# R40 register map
Vendor: Allwinner; Series: R40; File version: 0.1
CPU: CA7 0, little endian, MPU, FPU, double-precision FPU, 0 interrupt priority bits
Registers are 32-bit, read-write, reset 0x0 unless marked. A register's access mark holds for its fields unless they carry their own. Offsets are from the block's base; [hi:lo] are bit positions.

## SMHC0
Base 0x01C0F000
Same registers: SMHC1 0x01C10000, SMHC2 0x01C11000, SMHC3 0x01C12000
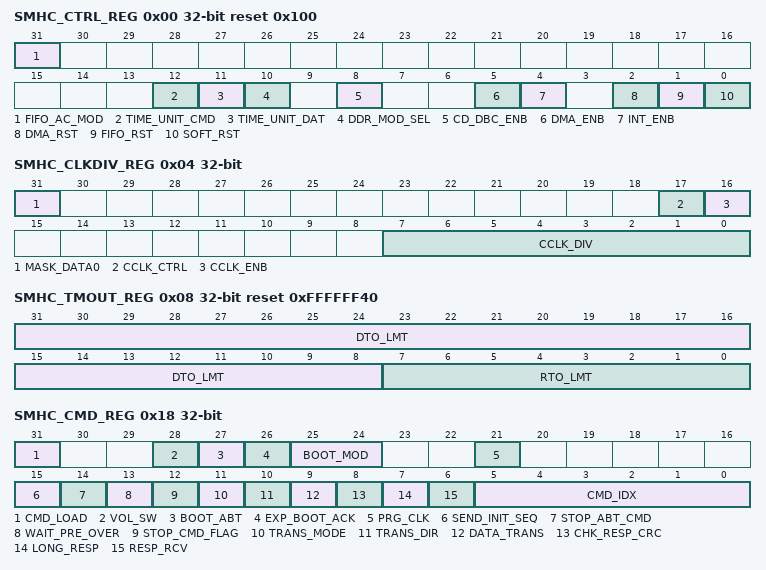
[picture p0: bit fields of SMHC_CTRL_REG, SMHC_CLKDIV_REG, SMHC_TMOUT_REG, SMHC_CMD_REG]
0x00 SMHC_CTRL_REG reset 0x100
  [31] FIFO_AC_MOD — FIFO Access Mode 0: DMA bus 1: AHB bus
    0=DMA (DMA bus); 1=AHB (AHB bus)
  [12] TIME_UNIT_CMD — Time unit for command line Time unit used to calculate command line time out value defined in RTO_LMT. 0: 1 card clock period 1: 256 card clock period
    0=1 card clock period; 1=256 card clock period
  [11] TIME_UNIT_DAT — Time unit for data line Time unit used to calculate data line time out value defined in . 0: 1 card clock period 1: 256 card clock period
    0=1 card clock period; 1=256 card clock period
  [10] DDR_MOD_SEL — DDR Mode Select 0: SDR mode 1: DDR mode
    0=SDR_mode; 1=DDR_mode
  [8] CD_DBC_ENB — Card Detect (Data[3] status) De-bounce Enable 0: Disable de-bounce 1: Enable de-bounce
    0=Disable de-bounce; 1=Enable de-bounce
  [5] DMA_ENB — DMA Global Enable 0: Disable DMA to transfer data, using AHB bus 1: Enable DMA to transfer data
    0=Disable DMA to transfer data, using AHB bus; 1=Enable DMA to transfer data
  [4] INT_ENB — Global Interrupt Enable 0: Disable interrupts 1: Enable interrupts
    0=Disable interrupts; 1=Enable interrupts
  [2] DMA_RST — DMA Reset
  [1] FIFO_RST — FIFO Reset 0: No change 1: Reset FIFO This bit is auto-cleared after completion of reset operation.
    0=No_change; 1=Reset FIFO This bit is auto-cleared after completion of reset operation
  [0] SOFT_RST — Software Reset 0: No change 1: Reset SD/MMC controller This bit is auto-cleared after completion of reset operation.
    0=No_change; 1=Reset SD/MMC controller This bit is auto-cleared after completion of reset operation
0x04 SMHC_CLKDIV_REG
  [31] MASK_DATA0 — 0: Do not mask data0 when update clock 1: Mask data0 when update clock
    0=Do not mask data0 when update clock; 1=Mask data0 when update clock
  [17] CCLK_CTRL — Card Clock Output Control 0: Card clock always on 1: Turn off card clock when FSM in IDLE state
    0=Card clock always on; 1=Turn off card clock when FSM in IDLE state
  [16] CCLK_ENB — Card Clock Enable 0: Card Clock off 1: Card Clock on
    0=Card_Clock_off; 1=Card_Clock_on
  [7:0] CCLK_DIV — Card clock divider n: Source clock is divided by 2*n.(n=0~255)
0x08 SMHC_TMOUT_REG reset 0xFFFFFF40
  [31:8] DTO_LMT — Data Timeout Limit
  [7:0] RTO_LMT — Response Timeout Limit
0x0C SMHC_BUSWID_REG
  [1:0] CARD_WID — Card width 00: 1-bit width 01: 4-bit width 1x: 8-bit width
    0=1-bit width; 1=4-bit width; 2=8-bit width
0x10 SMHC_BLKSIZ_REG reset 0x200
  [15:0] BLK_SZ — Block size
0x14 SMHC_BYTCNT_REG reset 0x200
  [31:0] BYTE_CNT — Byte counter Number of bytes to be transferred It should be integer multiple of Block Size for block transfers.
0x18 SMHC_CMD_REG
  [31] CMD_LOAD — Start Command. This bit is automatically cleared when current command is sent. If there is no any response error happened, a command complete interrupt bit (CMD_OVER) will be set in interrupt register. You should not write any other command before this bit is cleared, or a command busy interrupt bit (CMD_BUSY) will be set in interrupt register.
  [28] VOL_SW — Voltage Switch 0: Normal command 1: Voltage switch command, set for CMD11 only
    0=Normal command; 1=Voltage switch command, set for CMD11 only
  [27] BOOT_ABT — Boot Abort Setting this bit will terminate the boot operation.
  [26] EXP_BOOT_ACK — Expect Boot Acknowledge. When Software sets this bit along in mandatory boot operation, controller expects a boot acknowledge start pattern of 0-1-0 from the selected card.
  [25:24] BOOT_MOD — Boot Mode 00: Normal command 01: Mandatory Boot operation 10: Alternate Boot operation 11: Reserved
    0=Normal command; 1=Mandatory Boot operation; 2=Alternate Boot operation
  [21] PRG_CLK — Change Clock 0: Normal command 1: Change Card Clock; when this bit is set, controller will change clock domain and clock output. No command will be sent.
    0=Normal command; 1=Change Card Clock; when this bit is set, controller will change clock domain and clock output. No command will be sent.
  [15] SEND_INIT_SEQ — Send Initialization 0: Normal command sending 1: Send initialization sequence before sending this command.
    0=Normal command sending; 1=Send initialization sequence before sending this command
  [14] STOP_ABT_CMD — Stop Abort Command 0: Normal command sending 1: Send Stop or abort command to stop current data transfer in progress.(CMD12, CMD52 for writing `I/O Abort` in SDIO CCCR)
    0=Normal command sending; 1=Send Stop or abort command to stop current data transfer in progress.(CMD12, CMD52 for writing `I/O Abort` in SDIO CCCR)
  [13] WAIT_PRE_OVER — Wait Data Transfer Over 0: Send command at once, do not care of data transferring 1: Wait for data transfer completion before sending current command
    0=Send command at once, do not care of data transferring; 1=Wait for data transfer completion before sending current command
  [12] STOP_CMD_FLAG — Send Stop CMD Automatically (CMD12) 0: Do not send stop command at end of data transfer 1: Send stop command automatically at end of data transfer
    0=Do not send stop command at end of data transfer; 1=Send stop command automatically at end of data transfer
  [11] TRANS_MODE — Transfer Mode 0: Block data transfer command 1: Stream data transfer command
    0=Block data transfer command; 1=Stream data transfer command
  [10] TRANS_DIR — Transfer Direction 0: Read operation 1: Write operation
    0=Read operation; 1=Write operation
  [9] DATA_TRANS — Data Transfer 0: Without data transfer 1: With data transfer
    0=Without data transfer; 1=With data transfer
  [8] CHK_RESP_CRC — Check Response CRC 0: Do not check response CRC 1: Check response CRC
    0=Do not check response CRC; 1=Check response CRC
  [7] LONG_RESP — Response Type 0: Short Response (48 bit) 1: Long Response (136 bit)
    0=Short Response (48 bit); 1=Long Response (136 bit)
  [6] RESP_RCV — Response Receive 0: Command without Response 1: Command with Response
    0=Command_without_Response; 1=Command_with_Response
  [5:0] CMD_IDX — CMD Index Command index value
0x1C SMHC_CMDARG_REG
  [31:0] CMD_ARG — Command argument
0x20 SMHC_RESP0_REG
  [31:0] CMD_RESP0 ro — Response 0 Bit[31:0] of response
0x24 SMHC_RESP1_REG
  [31:0] CMD_RESP1 ro — Response 1 Bit[63:31] of response
0x28 SMHC_RESP2_REG
  [31:0] CMD_RESP2 ro — Response 2 Bit[95:64] of response
0x2C SMHC_RESP3_REG
  [31:0] CMD_RESP3 ro — Response 3 Bit[127:96] of response
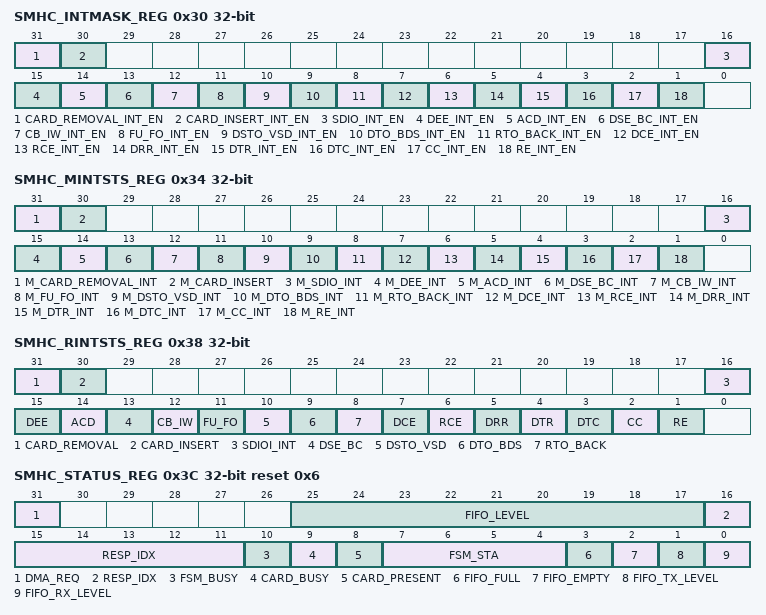
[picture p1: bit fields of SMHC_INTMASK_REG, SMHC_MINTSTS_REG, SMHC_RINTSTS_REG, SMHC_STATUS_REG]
0x30 SMHC_INTMASK_REG
  [31] CARD_REMOVAL_INT_EN — Card Removed Interrupt Enable
  [30] CARD_INSERT_INT_EN — Card Inserted Interrupt Enable
  [16] SDIO_INT_EN — SDIO Interrupt Enable
  [15] DEE_INT_EN — Data End-bit Error Interrupt Enable
  [14] ACD_INT_EN — Auto Command Done Interrupt Enable
  [13] DSE_BC_INT_EN — Data Start Error Interrupt Enable
  [12] CB_IW_INT_EN — Command Busy and Illegal Write Interrupt Enable
  [11] FU_FO_INT_EN — FIFO Underrun/Overflow Interrupt Enable
  [10] DSTO_VSD_INT_EN — Data Starvation Timeout/V1.8 Switch Done Interrupt Enable
  [9] DTO_BDS_INT_EN — Data Timeout/Boot Data Start Interrupt Enable
  [8] RTO_BACK_INT_EN — Response Timeout/Boot ACK Received Interrupt Enable
  [7] DCE_INT_EN — Data CRC Error Interrupt Enable
  [6] RCE_INT_EN — Response CRC Error Interrupt Enable
  [5] DRR_INT_EN — Data Receive Request Interrupt Enable
  [4] DTR_INT_EN — Data Transmit Request Interrupt Enable
  [3] DTC_INT_EN — Data Transfer Complete Interrupt Enable
  [2] CC_INT_EN — Command Complete Interrupt Enable
  [1] RE_INT_EN — Response Error Interrupt Enable
0x34 SMHC_MINTSTS_REG
  [31] M_CARD_REMOVAL_INT — Card Removed
  [30] M_CARD_INSERT — Card Inserted
  [16] M_SDIO_INT — SDIO Interrupt
  [15] M_DEE_INT — Data End-bit Error When set during receiving data, it means that host controller does not receive valid data end bit. When set during transmitting data, it means that host controller does not receive CRC status taken or received CRC status taken is negative.
  [14] M_ACD_INT — Auto Command Done When set, it means auto stop command(CMD12) completed.
  [13] M_DSE_BC_INT — Data Start Error When set during receiving data, it means that host controller found a error start bit. When set during transmitting data, it means that busy signal is cleared.
  [12] M_CB_IW_INT — Command Busy and Illegal Write
  [11] M_FU_FO_INT — FIFO Underrun/Overflow
  [10] M_DSTO_VSD_INT — Data Starvation Timeout/V1.8 Switch Done
  [9] M_DTO_BDS_INT — Data Timeout/Boot Data Start
  [8] M_RTO_BACK_INT — Response Timeout/Boot ACK Received
  [7] M_DCE_INT — Data CRC Error When set during receiving data, it means that the received data have data CRC error. When set during transmitting data, it means that the received CRC status taken is negative.
  [6] M_RCE_INT — Response CRC Error
  [5] M_DRR_INT — Data Receive Request When set, it means that there are enough data in FIFO during receiving data.
  [4] M_DTR_INT — Data Transmit Request When set, it means that there is enough space in FIFO during transmitting data.
  [3] M_DTC_INT — Data Transfer Complete
  [2] M_CC_INT — Command Complete
  [1] M_RE_INT — Response Error (no response or response CRC error) When set, Transmit Bit error or End Bit error or CMD Index error may occur.
0x38 SMHC_RINTSTS_REG
  [31] CARD_REMOVAL write-1-clears — Card Removed This is write-1-to-clear bit.
  [30] CARD_INSERT write-1-clears — Card Inserted This is write-1-to-clear bit.
  [16] SDIOI_INT write-1-clears — SDIO Interrupt This is write-1-to-clear bit.
  [15] DEE write-1-clears — Data End-bit Error When set during receiving data, it means that host controller does not receive valid data end bit. When set during transmitting data, it means that host controller does not receive CRC status taken. This is write-1-to-clear bit.
  [14] ACD write-1-clears — Auto Command Done When set, it means auto stop command(CMD12) completed. This is write-1-to-clear bit.
  [13] DSE_BC write-1-clears — Data Start Error When set during receiving data, it means that host controller found a error start bit. When set during transmitting data, it means that busy signal is cleared. This is write-1-to-clear bit.
  [12] CB_IW write-1-clears — Command Busy and Illegal Write This is write-1-to-clear bit.
  [11] FU_FO write-1-clears — FIFO Underrun/Overflow This is write-1-to-clear bit.
  [10] DSTO_VSD write-1-clears — Data Starvation Timeout/V1.8 Switch Done This is write-1-to-clear bit.
  [9] DTO_BDS write-1-clears — Data Timeout/Boot Data Start This is write-1-to-clear bit.
  [8] RTO_BACK write-1-clears — Response Timeout/Boot ACK Received This is write-1-to-clear bit.
  [7] DCE write-1-clears — Data CRC Error When set during receiving data, it means that the received data have data CRC error. When set during transmitting data, it means that the received CRC status taken is negative. This is write-1-to-clear bit.
  [6] RCE write-1-clears — Response CRC Error This is write-1-to-clear bit.
  [5] DRR write-1-clears — Data Receive Request When set, it means that there are enough data in FIFO during receiving data. This is write-1-to-clear bit.
  [4] DTR write-1-clears — Data Transmit Request When set, it means that there is enough space in FIFO during transmitting data. This is write-1-to-clear bit.
  [3] DTC write-1-clears — Data Transfer Complete This is write-1-to-clear bit.
  [2] CC write-1-clears — Command Complete This is write-1-to-clear bit.
  [1] RE write-1-clears — Response Error (no response or response CRC error) When set, Transmit Bit error or End Bit error or CMD Index error may occur. This is write-1-to-clear bit.
0x3C SMHC_STATUS_REG reset 0x6
  [31] DMA_REQ ro — DMA Request DMA request signal state
  [25:17] FIFO_LEVEL ro — FIFO Level Number of filled locations in FIFO
  [16:11] RESP_IDX ro — Response Index Index of previous response, including any auto-stop sent by controller
  [10] FSM_BUSY ro — Data FSM Busy Data transmit or receive state-machine is busy
  [9] CARD_BUSY ro — Card data busy Inverted version of DATA[0] 0: Card data not busy 1: Card data busy
    0=Card_data_not_busy; 1=Card_data_busy
  [8] CARD_PRESENT ro — Data[3] status level of DATA[3]; checks whether card is present 0: Card not present 1: Card present
    0=Card_not_present; 1=Card_present
  [7:4] FSM_STA ro — Command FSM states 0000: Idle 0001: Send init sequence 0010: TX CMD start bit 0011: TX CMD TX bit 0100: TX CMD index + argument 0101: TX CMD CRC7 0110: TX CMD end bit 0111: RX response start bit 1000: RX response IRQ response 1001: RX response TX bit 1010: RX response CMD index 1011: RX response data 1100: RX response CRC7 1101: RX response end bit 1110: CMD path wait NCC 1111: Wait; CMD-to-response turnaround
  [3] FIFO_FULL ro — FIFO full 0: FIFO not full 1: FIFO full
    0=FIFO (FIFO not full); 1=FIFO_full
  [2] FIFO_EMPTY ro — FIFO Empty 0: FIFO not empty 1: FIFO empty
    0=FIFO (FIFO not empty); 1=FIFO_empty
  [1] FIFO_TX_LEVEL ro — FIFO TX Water Level flag 0: FIFO didn`t reach transmit trigger level 1: FIFO reached transmit trigger level
    0=FIFO didn`t reach transmit trigger level; 1=FIFO reached transmit trigger level
  [0] FIFO_RX_LEVEL ro — FIFO TX Water Level flag 0: FIFO didn`t reach receive trigger level 1: FIFO reached receive trigger level
    0=FIFO didn`t reach receive trigger level; 1=FIFO reached receive trigger level
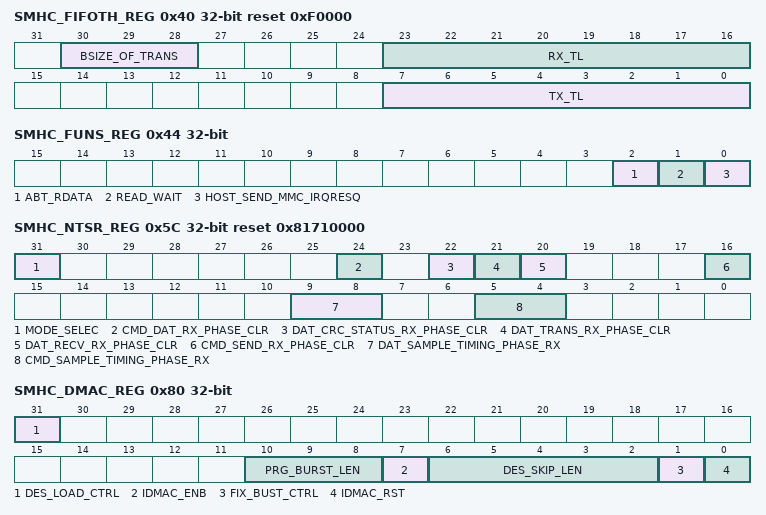
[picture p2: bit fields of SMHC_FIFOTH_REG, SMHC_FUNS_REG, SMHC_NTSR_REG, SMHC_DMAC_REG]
0x40 SMHC_FIFOTH_REG reset 0xF0000
  [30:28] BSIZE_OF_TRANS — Burst size of multiple transaction 000: 1 transfers 001: 4 010: 8 011: 16 (only SMHC2 support) Others: Reserved Should be programmed same as DMA controller multiple transaction size. The units for transfers are the DWORD. A single transfer would be signaled based on this value. Value should be sub-multiple of (RX_TL + 1) and (FIFO_DEPTH - TX_TL) Recommended: MSize = 16, TX_TL = 240, RX_TL = 15(SMHC2) MSize = 8, TX_TL = 248, RX_TL = 7(for SMHC0/1)
    0=1 transfers; 1=_4; 2=_8; 3=16 (only SMHC2 support) Others: Reserved Should be programmed same as DMA controller multiple transaction size. The units for transfers are the DWORD. A single transfer would be signaled based on this value. Value should be sub-multiple of (RX_TL + 1) and (FIFO_DEPTH - TX_TL) Recommended: MSize = 16, TX_TL = 240, RX_TL = 15(SMHC2) MSize = 8, TX_TL = 248, RX_TL = 7(for SMHC0/1)
  [23:16] RX_TL — RX Trigger Level 0x0~0xFE: RX Trigger Level is 0~254 0xFF reserved FIFO threshold when FIFO request host to receive data from FIFO. When FIFO data level is greater than this value, DMA request is raised if DMA enabled, or RX interrupt bit is set if interrupt enabled. At the end of packet, if the last transfer is less than this level, the value is ignored and relative request will be raised as usual. Recommended: 15 (means greater than 15)(SMHC2)
  [7:0] TX_TL — TX Trigger Level 0x1~0xFF: TX Trigger Level is 1~255 0x0: no trigger FIFO threshold when FIFO requests host to transmit data to FIFO. When FIFO data level is less than or equal to this value, DMA TX request is raised if DMA enabled, or TX request interrupt bit is set if interrupt enabled. At the end of packet, if the last transfer is less than this level, the value is ignored and relative request will be raised as usual. Recommended: 240(means less than or equal to 240)(SMHC2)
    0=no trigger FIFO threshold when FIFO requests host to transmit data to FIFO. When FIFO data level is less than or equal to this value, DMA TX request is raised if DMA enabled, or TX request interrupt bit is set if interrupt enabled. At the end of packet, if the last transfer is less than this level, the value is ignored and relative request will be raised as usual. Recommended: 240(means less than or equal to 240)(SMHC2)
0x44 SMHC_FUNS_REG
  [2] ABT_RDATA — Abort Read Data 0: Ignored 1: After suspend command is issued during read-transfer, software polls card to find when suspend happened. Once suspend occurs, software sets the bit to reset data state-machine, which is waiting for next block of data. Used in SDIO card suspends sequence. This bit is auto-cleared once controller reset to idle state.
    0=Ignored; 1=After suspend command is issued during read-transfer, software polls card to find when suspend happened. Once suspend occurs, software sets the bit to reset data state-machine, which is waiting for next block of data. Used in SDIO card suspends sequence. This bit is auto-cleared once controller reset to idle state.
  [1] READ_WAIT — Read Wait 0: Clear SDIO read wait 1: Assert SDIO read wait
    0=Clear SDIO read wait; 1=Assert SDIO read wait
  [0] HOST_SEND_MMC_IRQRESQ — Host Send MMC IRQ Response 0: Ignored 1: Send auto IRQ response When host is waiting MMC card interrupt response, setting this bit will make controller cancel wait state and return to idle state, at which time, controller will receive IRQ response sent by itself. This bit is auto-cleared after response is sent.
    0=Ignored; 1=Send auto IRQ response When host is waiting MMC card interrupt response, setting this bit will make controller cancel wait state and return to idle state, at which time, controller will receive IRQ response sent by itself. This bit is auto-cleared after response is sent.
0x48 SMHC_TBC_REG0
  [31:0] TBC0 ro — Transferred Count 0 Number of bytes transferred between card and internal FIFO. The register should be accessed in full to avoid read-coherency problems and read only after data transfer completes.
0x4C SMHC_TBC_REG1
  [31:0] TBC1 ro — Transferred Count 1 Number of bytes transferred between card and internal FIFO. The register should be accessed in full to avoid read-coherency problems and read only after data transfer completes.
0x54 SMHC_CSDC reset 0x3 — CRC Status Detect Control Register
  [3:0] CRC_DET_PARA — 0110: HS400 speed mode 0011: Other speed mode
    6=HS400 (HS400 speed mode); 3=Other speed mode
0x58 SMHC_A12A_REG reset 0xFFFF
  [15:0] SD_A12A — SD_A12A set the argument of command 12 automatically send by controller
0x5C SMHC_NTSR_REG reset 0x81710000
  [31] MODE_SELEC — 0: Old mode of Sample/Output Timing 1: New mode of Sample/Output Timing
    0=Old mode of Sample/Output Timing; 1=New mode of Sample/Output Timing
  [24] CMD_DAT_RX_PHASE_CLR — During update clock , command and data rx phase clear 0: Disable 1: Enable
    0=Disable; 1=Enable
  [22] DAT_CRC_STATUS_RX_PHASE_CLR — Before receive CRC status, data rx phase clear 0: Disable 1: Enable
    0=Disable; 1=Enable
  [21] DAT_TRANS_RX_PHASE_CLR — Before transfer data , data rx phase clear 0: Disable 1: Enable
    0=Disable; 1=Enable
  [20] DAT_RECV_RX_PHASE_CLR — Before receive data , data rx phase clear 0: Disable 1: Enable
    0=Disable; 1=Enable
  [16] CMD_SEND_RX_PHASE_CLR — Before send command, command rx phase clear 0: Disable 1: Enable
    0=Disable; 1=Enable
  [9:8] DAT_SAMPLE_TIMING_PHASE_RX — DAT_SAMPLE_TIMING_PHASE(RX) 00: Sample timing phase offset 90 01: Sample timing phase offset 180 10: Sample timing phase offset 270 11: Ignore
  [5:4] CMD_SAMPLE_TIMING_PHASE_RX — CMD_SAMPLE_TIMING_PHASE(RX) 00: Sample timing phase offset 90 01: Sample timing phase offset 180 10: Sample timing phase offset 270 11: Ignore
0x78 SMHC_HWRST_REG reset 0x1
  [0] HW_RST — 0: Reset 1: Active mode These bits cause the cards to enter pre-idle state, which requires them to be re-initialized.
    0=Reset; 1=Active mode These bits cause the cards to enter pre-idle state, which requires them to be re-initialized
0x80 SMHC_DMAC_REG
  [31] DES_LOAD_CTRL wo — When DMAC fetches a descriptor, if the valid bit of a descriptor is not set, DMAC FSM will go to the suspend state. Setting this bit will make DMAC re-fetch descriptor again and do the transfer normally.
  [10:8] PRG_BURST_LEN ro — Programmable Burst Length. These bits indicate the maximum number of beats to be performed in one IDMAC transaction. The IDMAC will always attempt to burst as specified in PBL each time it starts a Burst transfer on the host bus. The permissible values are 1, 4, 8, 16, 32, 64, 128 and 256. This value is the mirror of MSIZE of FIFOTH register. In order to change this value, write the required value to FIFOTH register. This is an encode value as follows. 000: 1 transfers 001: 4 transfers 010: 8 transfers 011: 16 transfers Transfer unit is 32bits. PBL is a read-only value.
    0=1 transfers; 1=4 transfers; 2=8 transfers; 3=16 transfers Transfer unit is 32bits. PBL is a read-only value.
  [7] IDMAC_ENB — IDMAC Enable. When set, the IDMAC is enabled. DE is read/write.
  [6:2] DES_SKIP_LEN — Descriptor Skip Length. Specifies the number of Word to skip between two unchained descriptors. This is applicable only for dual buffer structure. Default value is set to 4 DWORD.
  [1] FIX_BUST_CTRL — Fixed Burst. Controls whether the AHB Master interface performs fixed burst transfers or not. When set, the AHB will use only SINGLE, INCR4, INCR8 during start of normal burst transfers. When reset, the AHB will use SINGLE and INCR burst transfer operations.
  [0] IDMAC_RST — DMA Reset. When set, the DMA Controller resets all its internal registers. SWR is read/write. It is automatically cleared after 1 clock cycle.
0x84 SMHC_DLBA_REG
  [31:0] DES_BASE_ADDR — Start of Descriptor List. Contains the base address of the First Descriptor. The LSB bit[1:0] are ignored and taken as all-zero by the IDMAC internally. Hence these LSB bits are read-only.
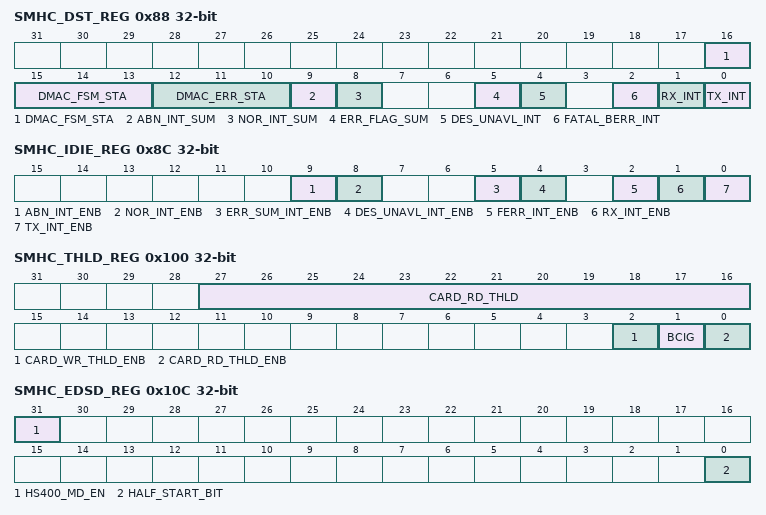
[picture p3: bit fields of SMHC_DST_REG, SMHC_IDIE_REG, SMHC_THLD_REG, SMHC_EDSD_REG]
0x88 SMHC_DST_REG
  [16:13] DMAC_FSM_STA ro — DMAC FSM present state. 0000: DMA_IDLE 0001: DMA_SUSPEND 0010: DESC_RD 0011: DESC_CHK 0100: DMA_RD_REQ_WAIT 0101: DMA_WR_REQ_WAIT 0110: DMA_RD 0111: DMA_WR 1000: DESC_CLOSE This bit is read-only.
    0=DMA_IDLE; 1=DMA_SUSPEND; 2=DESC_RD; 3=DESC_CHK; 4=DMA_RD_REQ_WAIT; 5=DMA_WR_REQ_WAIT; 6=DMA_RD; 7=DMA_WR; 8=DESC_CLOSE (DESC_CLOSE This bit is read-only.)
  [12:10] DMAC_ERR_STA ro — Error Bits. Indicates the type of error that caused a Bus Error. Valid only with Fatal Bus Error bit ( ) set. This field does not generate an interrupt. 001: Host Abort received during transmission 010: Host Abort received during reception Others: Reserved EB is read-only.
    1=Host_Abort_received_during_transmission; 2=Host Abort received during reception
  [9] ABN_INT_SUM write-1-clears — Abnormal Interrupt Summary. Logical OR of the following: IDSTS[2]: Fatal Bus Interrupt IDSTS[4]: DU bit Interrupt IDSTS[5]: Card Error Summary Interrupt Only unmasked bits affect this bit. This is a sticky bit and must be cleared each time a corresponding bit that causes AIS to be set is cleared. Writing a 1 clears this bit.
  [8] NOR_INT_SUM write-1-clears — Normal Interrupt Summary. Logical OR of the following: IDSTS[0]: Transmit Interrupt IDSTS[1]: Receive Interrupt Only unmasked bits affect this bit. This is a sticky bit and must be cleared each time a corresponding bit that causes NIS to be set is cleared. Writing a 1 clears this bit.
  [5] ERR_FLAG_SUM write-1-clears — Card Error Summary. Indicates the status of the transaction to/from the card; also present in RINTSTS. Indicates the logical OR of the following bits: EBE: End Bit Error RTO: Response Timeout/Boot ACK Timeout RCRC: Response CRC SBE: Start Bit Error DRTO: Data Read Timeout/BDS timeout DCRC: Data CRC for Receive RE: Response Error Writing a 1 clears this bit.
  [4] DES_UNAVL_INT write-1-clears — Descriptor Unavailable Interrupt. This bit is set when the descriptor is unavailable due to OWN bit = 0 (DES0[31] =0). Writing a 1 clears this bit.
  [2] FATAL_BERR_INT write-1-clears — Fatal Bus Error Interrupt. Indicates that a Bus Error occurred ( ). When this bit is set, the DMA disables all its bus accesses. Writing a `1` clears this bit.
  [1] RX_INT write-1-clears — Receive Interrupt. Indicates the completion of data reception for a descriptor. Writing a `1` clears this bit.
  [0] TX_INT write-1-clears — Transmit Interrupt. Indicates that data transmission is finished for a descriptor. Writing a `1` clears this bit.
0x8C SMHC_IDIE_REG
  [9] ABN_INT_ENB — Abnormal Interrupt Summary Enable. When set, an abnormal interrupt is enabled. This bit enables the following bits: IDINTEN[2]: Fatal Bus Error Interrupt IDINTEN[4]: DU Interrupt IDINTEN[5]: Card Error Summary Interrupt
  [8] NOR_INT_ENB — Normal Interrupt Summary Enable. When set, a normal interrupt is enabled. When reset, a normal interrupt is disabled. This bit enables the following bits: IDINTEN[0]: Transmit Interrupt IDINTEN[1]: Receive Interrupt
  [5] ERR_SUM_INT_ENB — Card Error summary Interrupt Enable. When set, it enables the Card Interrupt summary.
  [4] DES_UNAVL_INT_ENB — Descriptor Unavailable Interrupt. When set along with Abnormal Interrupt Summary Enable, the DU interrupt is enabled.
  [2] FERR_INT_ENB — Fatal Bus Error Enable. When set with Abnormal Interrupt Summary Enable, the Fatal Bus Error Interrupt is enabled. When reset, Fatal Bus Error Enable Interrupt is disabled.
  [1] RX_INT_ENB — Receive Interrupt Enable. When set with Normal Interrupt Summary Enable, Receive Interrupt is enabled. When reset, Receive Interrupt is disabled.
  [0] TX_INT_ENB — Transmit Interrupt Enable. When set with Normal Interrupt Summary Enable, Transmit Interrupt is enabled. When reset, Transmit Interrupt is disabled.
0x90 SMHC_CHDA_REG
  [31:0] CUR_DES_ADDR ro — Host Descriptor Address Pointer. Cleared on reset. Pointer updated by IDMAC during operation. This register points to the start address of the current descriptor read by the IDMAC.
0x94 SMHC_CBDA_REG
  [31:0] CUR_BUFF_ADDR ro — Host Buffer Address Pointer. Cleared on Reset. Pointer updated by IDMAC during operation. This register points to the current Data Buffer Address being accessed by the IDMAC.
0x100 SMHC_THLD_REG
  [27:16] CARD_RD_THLD — Card Read Threshold Size
  [2] CARD_WR_THLD_ENB — (only for SMHC2 ) Card Write Threshold Enable(HS400) 0: Card Write Threshold Disable 1: Card Write Threshold Enabled Host controller initiates write transfer only if card threshold amount of data is available in transmit FIFO
    0=Card_Write_Threshold_Disable; 1=Card Write Threshold Enabled Host controller initiates write transfer only if card threshold amount of data is available in transmit FIFO
  [1] BCIG — (only for SMHC2) Busy Clear Interrupt Generation 0: Busy Clear Interrupt Disabled 1: Busy Clear Interrupt Enabled The application can disable this feature if it does not want to wait for a Busy Clear Interrupt.
    0=Busy_Clear_Interrupt_Disabled; 1=Busy Clear Interrupt Enabled The application can disable this feature if it does not want to wait for a Busy Clear Interrupt
  [0] CARD_RD_THLD_ENB — Card Read Threshold Enable 0: Card Read Threshold Disable 1: Card Read Threshold Enable Host controller initiates Read Transfer only if amount of space is available in receive FIFO
    0=Card_Read_Threshold_Disable; 1=Card Read Threshold Enable Host controller initiates Read Transfer only if amount of space is available in receive FIFO
0x10C SMHC_EDSD_REG
  [31] HS400_MD_EN — HS400_MD_EN(for SMHC2 only) HS400 Mode Enable 0: Disable 1: Enable It is required to set to '1' before initiating any data transfer CMD in HS400 mode.
    0=Disable; 1=Enable It is required to set to '1' before initiating any data transfer CMD in HS400 mode
  [0] HALF_START_BIT — Control for start bit detection mechanism inside mstorage based on duration of start bit. For eMMC 4.5, start bit can be: 0: Full cycle 1: Less than one full cycle Set to 1 for eMMC 4.5 and above; set to 0 for SD applications.
    0=Full_cycle; 1=Less than one full cycle Set to 1 for eMMC 4.5 and above; set to 0 for SD applications
0x110 SMHC_RESP_CRC_REG
  [6:0] RESP_CRC ro — Response CRC Response CRC from device.
0x114 SMHC_DATA7_CRC_REG
  [31:0] DAT7_CRC ro — Data[7] CRC CRC in data[7] from device. In 8-bit DDR mode, the higher 16-bit indicates the CRC of even data, and the lower 16-bit indicates the CRC of odd data. In 4-bit DDR mode, it is not used. In SDR mode, the higher 16-bit indicates the CRC of all data.
0x118 SMHC_DATA6_CRC_REG
  [31:0] DAT6_CRC ro — Data[6] CRC CRC in data[6] from device. In 8-bit DDR mode, the higher 16-bit indicates the CRC of even data, and the lower 16-bit indicates the CRC of odd data. In 4-bit DDR mode, it is not used. In SDR mode, the higher 16-bit indicates the CRC of all data.
0x11C SMHC_DATA5_CRC_REG
  [31:0] DAT5_CRC ro — Data[5] CRC CRC in data[5] from device. In 8-bit DDR mode, the higher 16-bit indicates the CRC of even data, and the lower 16-bit indicates the CRC of odd data. In 4-bit DDR mode, it is not used. In SDR mode, the higher 16-bit indicates the CRC of all data.
0x120 SMHC_DATA4_CRC_REG
  [31:0] DAT4_CRC ro — Data[4] CRC CRC in data[4] from device. In 8-bit DDR mode, the higher 16-bit indicates the CRC of even data, and the lower 16-bit indicates the CRC of odd data. In 4-bit DDR mode, it is not used. In SDR mode, the higher 16-bit indicates the CRC of all data.
0x124 SMHC_DATA3_CRC_REG
  [31:0] DAT3_CRC ro — Data[3] CRC CRC in data[3] from device. In 8-bit DDR mode, the higher 16-bit indicates the CRC of even data, and the lower 16-bit indicates the CRC of odd data. In 4-bit DDR mode, it is not used. In SDR mode, the higher 16-bit indicates the CRC of all data.
0x128 SMHC_DATA2_CRC_REG
  [31:0] DAT2_CRC ro — Data[2] CRC CRC in data[2] from device. In 8-bit DDR mode, the higher 16-bit indicates the CRC of even data, and the lower 16-bit indicates the CRC of odd data. In 4-bit DDR mode, it is not used. In SDR mode, the higher 16-bit indicates the CRC of all data.
0x12C SMHC_DATA1_CRC_REG
  [31:0] DAT1_CRC ro — Data[1] CRC CRC in data[1] from device. In 8-bit DDR mode, the higher 16-bit indicates the CRC of even data, and the lower 16-bit indicates the CRC of odd data. In 4-bit DDR mode, it is not used. In SDR mode, the higher 16-bit indicates the CRC of all data.
0x130 SMHC_DATA0_CRC_REG
  [31:0] DAT0_CRC ro — Data[0] CRC CRC in data[0] from device. In 8-bit DDR mode, the higher 16-bit indicates the CRC of even data, and the lower 16-bit indicates the CRC of odd data. In 4-bit DDR mode, it is not used. In SDR mode, the higher 16-bit indicates the CRC of all data.
0x134 SMHC_CRC_STA_REG
  [2:0] CRC_STA ro — CRC Status CRC status from device in write operation 010: Positive CRC status token 101: Negative CRC status token
    2=Positive CRC status token; 5=Negative CRC status token
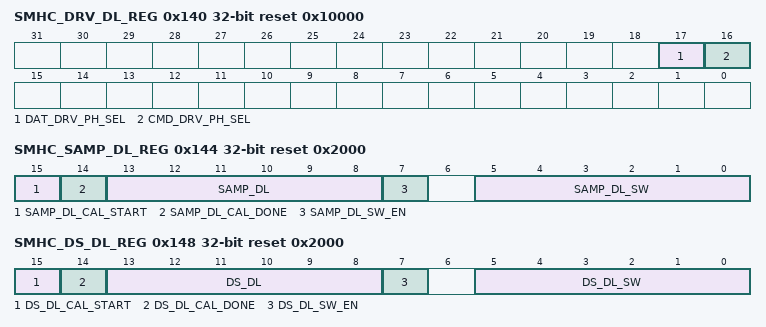
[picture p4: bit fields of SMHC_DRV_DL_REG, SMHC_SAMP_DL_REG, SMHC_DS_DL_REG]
0x140 SMHC_DRV_DL_REG reset 0x10000
  [17] DAT_DRV_PH_SEL — Data Drive Phase Select 0: Data drive phase offset is 90 at SDR mode, 45 at DDR mode, 90 at HS400 mode. 1: Data drive phase offset is 180 at SDR mode, 90 at DDR mode, 0 at HS400 mode.
    0=Data drive phase offset is 90 at SDR mode, 45 at DDR mode, 90 at HS400 mode; 1=Data drive phase offset is 180 at SDR mode, 90 at DDR mode, 0 at HS400 mode
  [16] CMD_DRV_PH_SEL — Command Drive Phase Select 0: Command drive phase offset is 90 at SDR mode, 45 at DDR mode, 90 at HS400 mode. 1: Command drive phase offset is 180 at SDR mode, 90 at DDR mode, 180 at HS400 mode.
    0=Command drive phase offset is 90 at SDR mode, 45 at DDR mode, 90 at HS400 mode; 1=Command drive phase offset is 180 at SDR mode, 90 at DDR mode, 180 at HS400 mode
0x144 SMHC_SAMP_DL_REG reset 0x2000
  [15] SAMP_DL_CAL_START — Sample Delay Calibration Start When set, start sample delay chain calibration.
  [14] SAMP_DL_CAL_DONE ro — Sample Delay Calibration Done When set, it means that sample delay chain calibration is done and the result of calibration is shown in .
  [13:8] SAMP_DL ro — Sample Delay It indicates the number of delay cells corresponding to current card clock. The delay time generated by these delay cells is equal to the cycle of card clock nearly. Generally, it is necessary to do drive delay calibration when card clock is changed. This bit is valid only when is set.
  [7] SAMP_DL_SW_EN — Sample Delay Software Enable When set, enable sample delay specified at .
  [5:0] SAMP_DL_SW — Sample Delay Software The relative delay between clock line and command line, data lines. It can be determined according to the value of , the cycle of card clock and device`s input timing requirement.
0x148 SMHC_DS_DL_REG reset 0x2000
  [15] DS_DL_CAL_START — Data Strobe Delay Calibration Start When set, start sample delay chain calibration.
  [14] DS_DL_CAL_DONE ro — Data Strobe Delay Calibration Done When set, it means that sample delay chain calibration is done and the result of calibration is shown in .
  [13:8] DS_DL ro — Data Strobe Delay It indicates the number of delay cells corresponding to current card clock. The delay time generated by these delay cells is equal to the cycle of SMHC`s clock nearly. This bit is valid only when is set.
  [7] DS_DL_SW_EN — Sample Delay Software Enable
  [5:0] DS_DL_SW — Data Strobe Delay Software
0x200 SMHC_FIFO_REG
  [31:0] TX/RX_FIFO — Data FIFO
